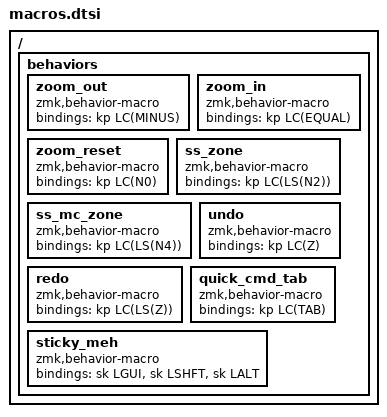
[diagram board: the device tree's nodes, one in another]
#include <dt-bindings/zmk/behaviors.h>
#include <dt-bindings/zmk/keys.h>
#include <zmk-helpers/helper.h>

// Zoom
ZMK_MACRO(zoom_out, bindings = <&kp LC(MINUS)>;)
ZMK_MACRO(zoom_in,  bindings = <&kp LC(EQUAL)>;)
ZMK_MACRO(zoom_reset,  bindings = <&kp LC(N0)>;)

// Screenshots
ZMK_MACRO(ss_zone, bindings = <&kp LC(LS(N2))>;) 
ZMK_MACRO(ss_mc_zone, bindings = <&kp LC(LS(N4))>;)

// Undo Redo
ZMK_MACRO(undo, bindings = <&kp LC(Z)>;) 
ZMK_MACRO(redo, bindings = <&kp LC(LS(Z))>;)

// Common actions
ZMK_MACRO(quick_cmd_tab,          bindings = <&kp LC(TAB)>;)

// Sticky modifier combinations - Meh key (GUI + Shift + Alt)
ZMK_MACRO(sticky_meh, bindings = <&sk LGUI>, <&sk LSHFT>, <&sk LALT>;)
